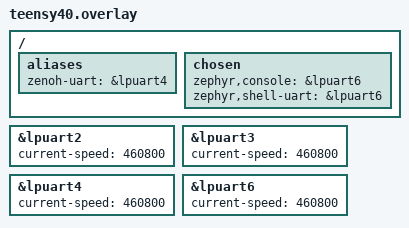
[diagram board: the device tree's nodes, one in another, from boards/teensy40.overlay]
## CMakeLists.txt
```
cmake_minimum_required(VERSION 3.20.0)

list(APPEND ZEPHYR_EXTRA_MODULES
    ${CMAKE_CURRENT_SOURCE_DIR}/../../modules/lib/zenoh-pico
)

find_package(Zephyr REQUIRED HINTS $ENV{ZEPHYR_BASE})
project(teensy40_zenoh_pub)

zephyr_compile_definitions(ZENOH_GENERIC)
zephyr_include_directories(${CMAKE_CURRENT_SOURCE_DIR}/include)

target_sources(app PRIVATE src/main.c)
```

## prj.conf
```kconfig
CONFIG_SERIAL=y
CONFIG_UART_INTERRUPT_DRIVEN=y

CONFIG_CONSOLE=y
CONFIG_UART_CONSOLE=y
CONFIG_LOG=n

CONFIG_NEWLIB_LIBC=y
CONFIG_POSIX_API=y
CONFIG_MAIN_STACK_SIZE=6144
CONFIG_HEAP_MEM_POOL_SIZE=65536

CONFIG_NETWORKING=y
CONFIG_NET_SOCKETS=y
CONFIG_NET_IPV4=y
CONFIG_NET_IPV6=y
CONFIG_NET_TCP=y
CONFIG_NET_UDP=y
CONFIG_DNS_RESOLVER=y

CONFIG_ZENOH_PICO=y
CONFIG_ZENOH_PICO_MULTI_THREAD=y
CONFIG_ZENOH_PICO_PUBLICATION=y
CONFIG_ZENOH_PICO_LINK_SERIAL=y
CONFIG_ZENOH_PICO_LINK_TCP=n
CONFIG_ZENOH_PICO_LINK_UDP_UNICAST=n
CONFIG_ZENOH_PICO_LINK_UDP_MULTICAST=n
CONFIG_ZENOH_PICO_SCOUTING=n
CONFIG_ZENOH_PICO_LINK_WS=n
CONFIG_ZENOH_PICO_RAWETH_TRANSPORT=n

CONFIG_TIMESLICING=y
CONFIG_TIMESLICE_SIZE=1
CONFIG_TIMESLICE_PRIORITY=0
```

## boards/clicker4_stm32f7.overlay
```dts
/ {
    aliases {
        zenoh-uart = &usart2;
    };
};

&usart2 {
    status = "okay";
    current-speed = <230400>;
};
```

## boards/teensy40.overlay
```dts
/ {
    aliases {
        zenoh-uart = &lpuart4;
    };

    chosen {
        zephyr,console = &lpuart6;
        zephyr,shell-uart = &lpuart6;
    };
};

&lpuart2 {
    status = "okay";
    current-speed = <460800>;
};

&lpuart3 {
    status = "okay";
    current-speed = <460800>;
};
&lpuart4 {
    status = "okay";
    current-speed = <460800>;
};


&lpuart6 {
    status = "okay";
    current-speed = <460800>;
};
```

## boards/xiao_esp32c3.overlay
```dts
/ {
    aliases {
        zenoh-uart = &uart0;
    };

    chosen {
        zephyr,console = &usb_serial;
        zephyr,shell-uart = &usb_serial;
    };
};

&uart0 {
    status = "okay";
    current-speed = <230400>;
};
```

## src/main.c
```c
#include <stdio.h>

#include <zephyr/device.h>
#include <zephyr/devicetree.h>
#include <zephyr/kernel.h>
#include <zephyr/sys/printk.h>

#include <zenoh-pico.h>

#define MODE "client"
#define KEYEXPR "demo/teensy40/heartbeat"
#define STARTUP_DELAY_MS 2000U
#define PUB_PERIOD_MS 1U

#if !DT_NODE_EXISTS(DT_ALIAS(zenoh_uart))
#error "Missing devicetree alias 'zenoh-uart'"
#endif
#define ZENOH_UART_NODE DT_ALIAS(zenoh_uart)

#if !DT_NODE_HAS_PROP(ZENOH_UART_NODE, current_speed)
#error "'zenoh-uart' node must define current-speed"
#endif
#define ZENOH_BAUDRATE DT_PROP(ZENOH_UART_NODE, current_speed)

static int open_session(z_owned_session_t *session, const char *locator)
{
    z_owned_config_t config;

    if (z_config_default(&config) < 0) {
        return -1;
    }
    if (zp_config_insert(z_loan_mut(config), Z_CONFIG_MODE_KEY, MODE) < 0) {
        z_drop(z_move(config));
        return -1;
    }
    if (zp_config_insert(z_loan_mut(config), Z_CONFIG_CONNECT_KEY, locator) < 0) {
        z_drop(z_move(config));
        return -1;
    }
    if (z_open(session, z_move(config), NULL) < 0) {
        return -1;
    }
    if (zp_start_read_task(z_loan_mut(*session), NULL) < 0) {
        z_drop(z_move(*session));
        return -1;
    }
    if (zp_start_lease_task(z_loan_mut(*session), NULL) < 0) {
        z_drop(z_move(*session));
        return -1;
    }
    return 0;
}

int main(void)
{
    const struct device *uart_dev = DEVICE_DT_GET(ZENOH_UART_NODE);
    const char *uart_name = DEVICE_DT_NAME(ZENOH_UART_NODE);
    z_owned_session_t session;
    z_owned_publisher_t pub;
    z_view_keyexpr_t ke;
    char locator[96];
    uint32_t count = 0;

    if (!device_is_ready(uart_dev)) {
        printk("zenoh: UART not ready: %s\n", uart_name);
        return -1;
    }

    snprintk(locator, sizeof(locator), "serial/%s#baudrate=%u", uart_name, (unsigned int)ZENOH_BAUDRATE);
    printk("fw: teensy40-zenoh-pub-min\n");
    printk("zenoh: waiting %u ms for serial to settle...\n", (unsigned int)STARTUP_DELAY_MS);
    k_sleep(K_MSEC(STARTUP_DELAY_MS));
    printk("zenoh: locator=%s\n", locator);
    printk("zenoh: keyexpr=%s\n", KEYEXPR);

    printk("z_open...\n");
    if (open_session(&session, locator) < 0) {
        printk("z_open failed\n");
        return -1;
    }
    printk("z_open ok\n");

    z_view_keyexpr_from_str_unchecked(&ke, KEYEXPR);
    if (z_declare_publisher(z_loan(session), &pub, z_loan(ke), NULL) < 0) {
        printk("z_declare_publisher failed\n");
        z_drop(z_move(session));
        return -1;
    }
    printk("declare ok\n");

    while (1) {
        char buf[64];
        z_owned_bytes_t payload;
        int len = snprintk(buf, sizeof(buf), "teensy40-count=%u", (unsigned int)count++);
        if (len < 0) {
            printk("format failed\n");
            break;
        }
        if (z_bytes_copy_from_str(&payload, buf) < 0) {
            printk("bytes alloc failed\n");
            break;
        }
        if (z_publisher_put(z_loan(pub), z_move(payload), NULL) < 0) {
            printk("put failed\n");
            break;
        }
        if ((count % 50U) == 0U) {
            printk("zenoh: published %u messages\n", (unsigned int)count);
        }
        k_sleep(K_MSEC(PUB_PERIOD_MS));
    }

    z_drop(z_move(pub));
    z_drop(z_move(session));
    return -1;
}
```

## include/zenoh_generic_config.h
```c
#ifndef TEENSY40_ZENOH_GENERIC_CONFIG_H
#define TEENSY40_ZENOH_GENERIC_CONFIG_H

/* Runtime tuning defaults */
#ifndef Z_FRAG_MAX_SIZE
#define Z_FRAG_MAX_SIZE 4096
#endif
#ifndef Z_BATCH_UNICAST_SIZE
#define Z_BATCH_UNICAST_SIZE 2048
#endif
#ifndef Z_BATCH_MULTICAST_SIZE
#define Z_BATCH_MULTICAST_SIZE 2048
#endif
#ifndef Z_CONFIG_SOCKET_TIMEOUT
#define Z_CONFIG_SOCKET_TIMEOUT 100
#endif
#ifndef Z_TRANSPORT_LEASE
#define Z_TRANSPORT_LEASE 10000
#endif
#ifndef Z_TRANSPORT_LEASE_EXPIRE_FACTOR
#define Z_TRANSPORT_LEASE_EXPIRE_FACTOR 3
#endif
#ifndef ZP_PERIODIC_SCHEDULER_MAX_TASKS
#define ZP_PERIODIC_SCHEDULER_MAX_TASKS 64
#endif

/* Feature defaults: Zephyr Kconfig compile definitions override these */
#ifndef Z_FEATURE_UNSTABLE_API
/* Keep disabled by default */
#endif
#ifndef Z_FEATURE_MULTI_THREAD
#define Z_FEATURE_MULTI_THREAD 1
#endif
#ifndef Z_FEATURE_PUBLICATION
#define Z_FEATURE_PUBLICATION 1
#endif
#ifndef Z_FEATURE_ADVANCED_PUBLICATION
#define Z_FEATURE_ADVANCED_PUBLICATION 0
#endif
#ifndef Z_FEATURE_SUBSCRIPTION
#define Z_FEATURE_SUBSCRIPTION 0
#endif
#ifndef Z_FEATURE_ADVANCED_SUBSCRIPTION
#define Z_FEATURE_ADVANCED_SUBSCRIPTION 0
#endif
#ifndef Z_FEATURE_QUERY
#define Z_FEATURE_QUERY 0
#endif
#ifndef Z_FEATURE_QUERYABLE
#define Z_FEATURE_QUERYABLE 0
#endif
#ifndef Z_FEATURE_LIVELINESS
#define Z_FEATURE_LIVELINESS 1
#endif
#ifndef Z_FEATURE_RAWETH_TRANSPORT
#define Z_FEATURE_RAWETH_TRANSPORT 0
#endif
#ifndef Z_FEATURE_INTEREST
#define Z_FEATURE_INTEREST 1
#endif
#ifndef Z_FEATURE_LINK_TCP
#define Z_FEATURE_LINK_TCP 0
#endif
#ifndef Z_FEATURE_LINK_BLUETOOTH
#define Z_FEATURE_LINK_BLUETOOTH 0
#endif
#ifndef Z_FEATURE_LINK_WS
#define Z_FEATURE_LINK_WS 0
#endif
#ifndef Z_FEATURE_LINK_SERIAL
#define Z_FEATURE_LINK_SERIAL 1
#endif
#ifndef Z_FEATURE_LINK_SERIAL_USB
#define Z_FEATURE_LINK_SERIAL_USB 0
#endif
#ifndef Z_FEATURE_LINK_TLS
#define Z_FEATURE_LINK_TLS 0
#endif
#ifndef Z_FEATURE_SCOUTING
#define Z_FEATURE_SCOUTING 0
#endif
#ifndef Z_FEATURE_LINK_UDP_MULTICAST
#define Z_FEATURE_LINK_UDP_MULTICAST 0
#endif
#ifndef Z_FEATURE_LINK_UDP_UNICAST
#define Z_FEATURE_LINK_UDP_UNICAST 0
#endif
#ifndef Z_FEATURE_MULTICAST_TRANSPORT
#define Z_FEATURE_MULTICAST_TRANSPORT 0
#endif
#ifndef Z_FEATURE_UNICAST_TRANSPORT
#define Z_FEATURE_UNICAST_TRANSPORT 1
#endif
#ifndef Z_FEATURE_FRAGMENTATION
#define Z_FEATURE_FRAGMENTATION 1
#endif
#ifndef Z_FEATURE_ENCODING_VALUES
#define Z_FEATURE_ENCODING_VALUES 1
#endif
#ifndef Z_FEATURE_TCP_NODELAY
#define Z_FEATURE_TCP_NODELAY 1
#endif
#ifndef Z_FEATURE_LOCAL_SUBSCRIBER
#define Z_FEATURE_LOCAL_SUBSCRIBER 0
#endif
#ifndef Z_FEATURE_LOCAL_QUERYABLE
#define Z_FEATURE_LOCAL_QUERYABLE 0
#endif
#ifndef Z_FEATURE_SESSION_CHECK
#define Z_FEATURE_SESSION_CHECK 1
#endif
#ifndef Z_FEATURE_BATCHING
#define Z_FEATURE_BATCHING 1
#endif
#ifndef Z_FEATURE_BATCH_TX_MUTEX
#define Z_FEATURE_BATCH_TX_MUTEX 0
#endif
#ifndef Z_FEATURE_BATCH_PEER_MUTEX
#define Z_FEATURE_BATCH_PEER_MUTEX 0
#endif
#ifndef Z_FEATURE_MATCHING
#define Z_FEATURE_MATCHING 1
#endif
#ifndef Z_FEATURE_RX_CACHE
#define Z_FEATURE_RX_CACHE 0
#endif
#ifndef Z_FEATURE_UNICAST_PEER
#define Z_FEATURE_UNICAST_PEER 1
#endif
#ifndef Z_FEATURE_AUTO_RECONNECT
#define Z_FEATURE_AUTO_RECONNECT 1
#endif
#ifndef Z_FEATURE_MULTICAST_DECLARATIONS
#define Z_FEATURE_MULTICAST_DECLARATIONS 0
#endif
#ifndef Z_FEATURE_PERIODIC_TASKS
#define Z_FEATURE_PERIODIC_TASKS 0
#endif

#endif /* TEENSY40_ZENOH_GENERIC_CONFIG_H */
```
